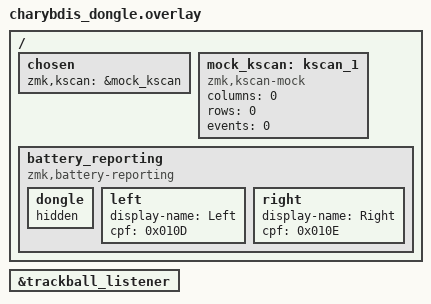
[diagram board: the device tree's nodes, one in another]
#include "charybdis.dtsi"
#include "split_input_common.dtsi"
/ {
    chosen {
        zmk,kscan = &mock_kscan;
    };

    mock_kscan: kscan_1 {
        compatible = "zmk,kscan-mock";
        columns = <0>;
        rows = <0>;
        events = <0>;
    };

	battery_reporting: battery_reporting {
        compatible = "zmk,battery-reporting";

        dongle {
            hidden;
        };
        left {
            display-name = "Left";
            cpf = <0x010D>;
        };
        right {
            display-name = "Right";
            cpf = <0x010E>;
        };
    };
};

&trackball_listener {
    status = "okay";
};
